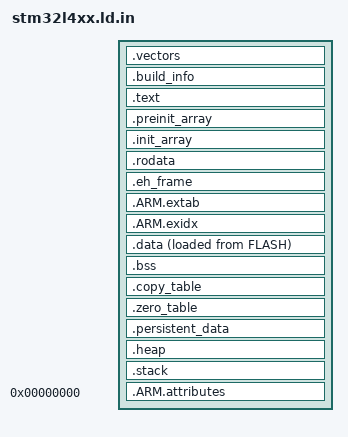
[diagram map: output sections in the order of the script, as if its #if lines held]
/*
 * Linker script for STM32L4xx series devices. This script is intended to be
 * pre-processed using the C preprocessor before being used.
 *
 * The following MEMORY regions must be defined elsewhere:
 * FLASH, SRAM1, SRAM2
 *
 * The following symbols are assumed to exist in the code:
 *   Reset_Handler : Entry point for execution
 *
 * The following preprocessor symbols may be be defined to a true or false value
 * to control the inclusion or exclusion of sections
 * KEEP_UNWIND_TABLES
 * KEEP_EXCEPTIONS
 * STARTUP_COPY_MULTIPLE
 * STARTUP_CLEAR_BSS_MULTIPLE
 *
 * The following symbols may be defined to a numeric value
 * HEAP_SIZE
 * MIN_STACK_SIZE
 *
 */

ENTRY(Reset_Handler)

/* Ensure that the vector tables get pulled in */
EXTERN(kArmExceptionVectorTable)
EXTERN(kStm32l4xxInterruptVectorTable)

SECTIONS
{
    .vectors : {
        /* Exception and interrupt vectors */
        KEEP(*(.armcm4f_vector_table*))
        KEEP(*(.stm32l4xx_vector_table*))
    } >FLASH

    .build_info ALIGN(4) : {
        __build_info_start = .;
        KEEP(*(.build_info))
        __build_info_end = .;
    } >FLASH

    /* Normal code */
    .text : {
        *(.text*)
    } >FLASH

    /* Array of pre-initialization functions */
    .preinit_array : ALIGN(4) {
        __preinit_array_start = .;
        KEEP(*(.preinit_array))
        __preinit_array_end = .;
    } >FLASH

    /* Array of initialization functions */
    .init_array : ALIGN(4) {
        __init_array_start = .;
        KEEP(*(SORT(.init_array.*)))
        KEEP(*(.init_array))
        __init_array_end = .;
    } >FLASH

    /* Read-only data */
    .rodata : ALIGN(4) {
        *(vtable)
        *(.rodata*)
    } >FLASH

#if KEEP_EXCEPTIONS
    /* Exception handling frame */
    .eh_frame : {
        KEEP(*(.eh_frame*))
    } > FLASH

    /* ARM exception tables */
    .ARM.extab : {
        *(.ARM.extab* .gnu.linkonce.armextab.*)
    } >FLASH
#endif

#if KEEP_UNWIND_TABLES
    /* ARM stack unwinding tables */
    .ARM.exidx : {
        __exidx_start = .;
        *(.ARM.exidx* .gnu.linkonce.armexidx.*)
        __exidx_end = .;
    } >FLASH
#endif

    .data : ALIGN(4) {
        __data_start = .;
        *(.data*)
        . = ALIGN(4);
        __data_end = .;
    } >SRAM1 AT>FLASH

    __data_load_start = LOADADDR(.data);

    .bss ALIGN(16) (NOLOAD) : {
        __bss_start = .;
        *(.bss*)
        *(COMMON)
        . = ALIGN(4);
        __bss_end = .;
    } >SRAM1

#if STARTUP_COPY_MULTIPLE
    /* To use define __STARTUP_COPY_MULTIPLE in startup_ARMCMx.S */
    .copy_table ALIGN(4) : {
        __copy_table_start = .;
        LONG (__data_load_start)
        LONG (__data_start)
        LONG (__data_end - __data_start)
        LONG (__data2_load_start)
        LONG (__data2_start)
        LONG (__data2_end - __data2_start)
        __copy_table_end = .;
    } >FLASH
#endif

#if STARTUP_CLEAR_BSS_MULTIPLE
    /* To use define __STARTUP_CLEAR_BSS_MULTIPLE in startup_ARMCMx.S */
    .zero_table ALIGN(4) : {
        __zero_table_start = .;
        LONG (__bss_start)
        LONG (__bss_end - __bss_start)
        LONG (__bss2_start)
        LONG (__bss2_end - __bss2_start)
        __zero_table_end = .;
    } >FLASH
#endif

    .persistent_data ALIGN(4) (NOLOAD) : {
        __persistent_start = .;
        *(.persistent*)
        __persistent_end = .;
    } >SRAM1

#ifdef HEAP_SIZE
    .heap ALIGN(4) (NOLOAD) : {
        __heap_start = .;
        . = . + HEAP_SIZE;
        . = ALIGN(4);
        __heap_end = .;
    } >SRAM1

    /* Newlib uses the distinctly named 'end' symbol for the start-of-heap marker */
    PROVIDE_HIDDEN(end = __heap_start);
#endif

    /* Stack gets all the remaining RAM */
    /* There is are stack_dummy sections anywhere */
    .stack ALIGN(4) (NOLOAD) : {
        __stack_bottom = .;
        *(.stack_dummy*)
        __stack_top = ORIGIN(SRAM1) + LENGTH(SRAM1);
        __stack_size = __stack_top - __stack_bottom;
    } >SRAM1

#ifdef MIN_STACK_SIZE
    /* Check that stack meets or exceeds minimum size */
    ASSERT(__stack_size >= MIN_STACK_SIZE, "Stack size smaller than specified minimum");
#endif

    /* Discard unused sections explicitly */
    /DISCARD/ : {
        /* GCC no longer uses .init and .fini sections */
        *(.init)
        *(.fini)

        /* We never return from main, so discard global destructors */
        *(.fini_array*)

#if !KEEP_EXCEPTIONS
        *(.eh_frame*)
        *(.ARM.extab* .gnu.linkonce.armextab.*)
#endif

#if !KEEP_UNWIND_TABLES
        *(.ARM.exidx* .gnu.linkonce.armexidx.*)
#endif

    }

    /* Keep build attributes in ELF file for analysis */
    .ARM.attributes 0 : {
        *(.ARM.attributes*)
    }
}
